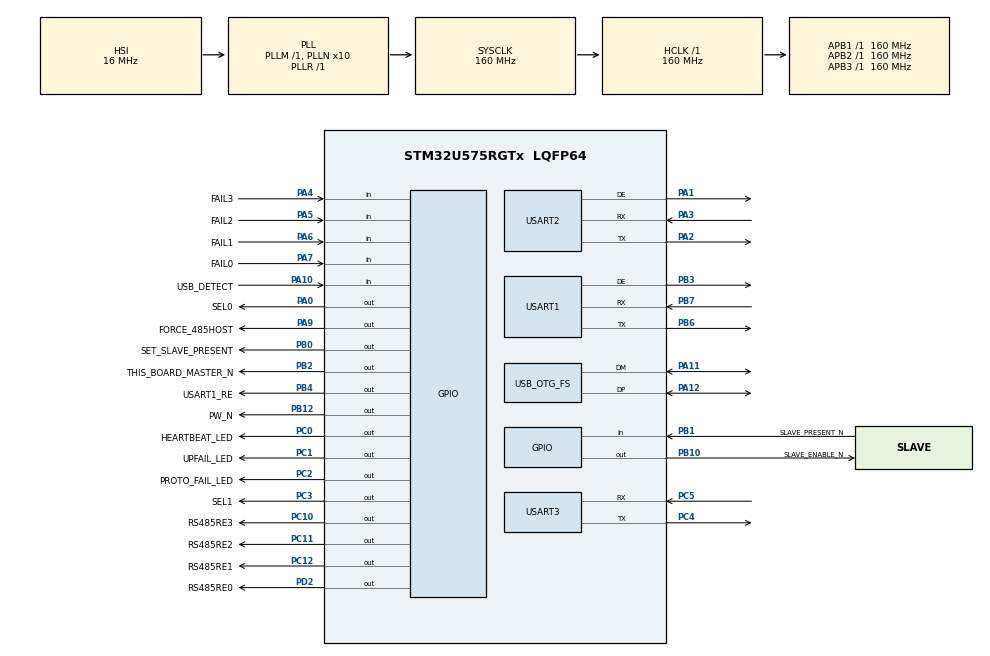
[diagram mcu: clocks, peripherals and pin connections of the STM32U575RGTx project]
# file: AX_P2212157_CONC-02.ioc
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CORTEX_M33_NS.userName=CORTEX_M33
GPDMA1.DIRECTION_GPDMACH0=DMA_MEMORY_TO_PERIPH
GPDMA1.IPHANDLE_GPDMACH0-SIMPLEREQUEST_GPDMACH0=__NULL
GPDMA1.REQUEST_GPDMACH0=GPDMA1_REQUEST_USART2_TX
GPDMA1.SRCINC_GPDMACH0=DMA_SINC_INCREMENTED
GPDMA1.TRANSFERALLOCATEDPORTDEST_GPDMACH0=DMA_DEST_ALLOCATED_PORT1
Mcu.Family=STM32U5
Mcu.Name=STM32U575RGTx
Mcu.Package=LQFP64
NVIC.GPDMA1_Channel0_IRQn=true\:0\:0\:false\:false\:true\:false\:true\:true
NVIC.OTG_FS_IRQn=true\:0\:0\:false\:false\:true\:true\:true\:true
NVIC.PriorityGroup=NVIC_PRIORITYGROUP_4
NVIC.USART1_IRQn=true\:0\:0\:false\:false\:true\:true\:true\:true
NVIC.USART2_IRQn=true\:0\:0\:false\:false\:true\:true\:true\:true
NVIC.USART3_IRQn=true\:0\:0\:false\:false\:true\:true\:true\:true
PA0.GPIO_Label=SEL0
PA0.Signal=GPIO_Output
PA1.Mode=Hardware Flow Control (RS485)
PA1.Signal=USART2_DE
PA10.GPIO_Label=USB_DETECT
PA10.Signal=GPIO_Input
PA11.Mode=Device_Only
PA11.Signal=USB_OTG_FS_DM
PA12.Mode=Device_Only
PA12.Signal=USB_OTG_FS_DP
PA13\ (JTMS/SWDIO).Mode=Serial_Wire
PA13\ (JTMS/SWDIO).Signal=DEBUG_JTMS-SWDIO
PA14\ (JTCK/SWCLK).Mode=Serial_Wire
PA14\ (JTCK/SWCLK).Signal=DEBUG_JTCK-SWCLK
PA2.Mode=Asynchronous
PA2.Signal=USART2_TX
PA3.Mode=Asynchronous
PA3.Signal=USART2_RX
PA4.GPIO_Label=FAIL3
PA4.GPIO_PuPd=GPIO_PULLUP
PA4.Signal=GPIO_Input
PA5.GPIO_Label=FAIL2
PA5.GPIO_PuPd=GPIO_PULLUP
PA5.Signal=GPIO_Input
PA6.GPIO_Label=FAIL1
PA6.GPIO_PuPd=GPIO_PULLUP
PA6.Signal=GPIO_Input
PA7.GPIO_Label=FAIL0
PA7.GPIO_PuPd=GPIO_PULLUP
PA7.Signal=GPIO_Input
PA9.GPIO_Label=FORCE_485HOST
PA9.Signal=GPIO_Output
PB0.GPIO_Label=SET_SLAVE_PRESENT
PB0.Signal=GPIO_Output
PB1.GPIO_Label=SLAVE_PRESENT_N
PB1.Signal=GPIO_Input
PB10.GPIO_Label=SLAVE_ENABLE_N
PB10.Signal=GPIO_Output
PB12.GPIO_Label=PW_N
PB12.Signal=GPIO_Output
PB2.GPIO_Label=THIS_BOARD_MASTER_N
PB2.Signal=GPIO_Output
PB3\ (JTDO/TRACESWO).Mode=Hardware Flow Control (RS485)
PB3\ (JTDO/TRACESWO).Signal=USART1_DE
PB4\ (NJTRST).GPIO_Label=USART1_RE
PB4\ (NJTRST).Signal=GPIO_Output
PB6.Mode=Asynchronous
PB6.Signal=USART1_TX
PB7.Mode=Asynchronous
PB7.Signal=USART1_RX
PC0.GPIO_Label=HEARTBEAT_LED
PC0.Signal=GPIO_Output
PC1.GPIO_Label=UPFAIL_LED
PC1.Signal=GPIO_Output
PC10.GPIO_Label=RS485RE3
PC10.Signal=GPIO_Output
PC11.GPIO_Label=RS485RE2
PC11.Signal=GPIO_Output
PC12.GPIO_Label=RS485RE1
PC12.Signal=GPIO_Output
PC2.GPIO_Label=PROTO_FAIL_LED
PC2.Signal=GPIO_Output
PC3.GPIO_Label=SEL1
PC3.Signal=GPIO_Output
PC4.Mode=Asynchronous
PC4.Signal=USART3_TX
PC5.Mode=Asynchronous
PC5.Signal=USART3_RX
PD2.GPIO_Label=RS485RE0
PD2.Signal=GPIO_Output
ProjectManager.HeapSize=0x200
ProjectManager.StackSize=0x400
ProjectManager.TargetToolchain=STM32CubeIDE
RCC.ADCFreq_Value=16000000
RCC.AHBFreq_Value=160000000
RCC.APB1Freq_Value=160000000
RCC.APB1TimFreq_Value=160000000
RCC.APB2Freq_Value=160000000
RCC.APB2TimFreq_Value=160000000
RCC.APB3Freq_Value=160000000
RCC.CortexFreq_Value=160000000
RCC.EPOD_VALUE=16000000
RCC.HCLKFreq_Value=160000000
RCC.HSE_VALUE=16000000
RCC.HSI48_VALUE=48000000
RCC.HSI_VALUE=16000000
RCC.LSE_VALUE=32768
RCC.LSIDIV_VALUE=32000
RCC.MSI_VALUE=4000000
RCC.PLL1R=1
RCC.PLLFRACN=0
RCC.PLLN=10
RCC.PLLSourceVirtual=RCC_PLLSOURCE_HSI
RCC.SYSCLKFreq_VALUE=160000000
RCC.SYSCLKSource=RCC_SYSCLKSOURCE_PLLCLK
RCC.USBFreq_Value=48000000
RCC.VCOOutputFreq_Value=160000000
USART1.VirtualMode-Asynchronous=VM_ASYNC
USART1.VirtualMode-Hardware\ Flow\ Control\ (RS485)=VM_ASYNC
USART2.VirtualMode-Asynchronous=VM_ASYNC
USART2.VirtualMode-Hardware\ Flow\ Control\ (RS485)=VM_ASYNC
USART3.VirtualMode-Asynchronous=VM_ASYNC
USB_OTG_FS.VirtualMode=Device_Only
VP_CRC_VS_CRC.Mode=CRC_Activate
VP_GPDMA1_VS_GPDMACH0.Mode=SIMPLEREQUEST_GPDMACH0
VP_ICACHE_VS_ENABLE_ICACHE_MEMORY.Mode=Memoryregions
VP_ICACHE_VS_ICACHE.Mode=DefaultMode
VP_LPBAMQUEUE_VS_QUEUE.Mode=QUEUEMODE
VP_LPBAM_VS_SIG1.Mode=SmartRun
VP_LPBAM_VS_SIG4.Mode=LPDMA1
VP_MEMORYMAP_VS_MEMORYMAP.Mode=CurAppReg
VP_PWR_VS_SECSignals.Mode=Security/Privilege
VP_RNG_VS_RNG.Mode=RNG_Activate
board=custom

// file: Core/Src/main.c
/* USER CODE BEGIN Header */
/**
  ******************************************************************************
  * @file           : main.c
  * @brief          : Main program body
  ******************************************************************************
  * @attention
  *
  * Copyright (c) 2024 STMicroelectronics.
  * All rights reserved.
  *
  * This software is licensed under terms that can be found in the LICENSE file
  * in the root directory of this software component.
  * If no LICENSE file comes with this software, it is provided AS-IS.
  *
  ******************************************************************************
  */
/* USER CODE END Header */
#include "main.h"

CRC_HandleTypeDef hcrc;

RNG_HandleTypeDef hrng;

UART_HandleTypeDef huart1;
UART_HandleTypeDef huart2;
UART_HandleTypeDef huart3;
DMA_HandleTypeDef handle_GPDMA1_Channel0;

PCD_HandleTypeDef hpcd_USB_OTG_FS;

void SystemClock_Config(void);
static void MX_GPIO_Init(void);
static void MX_GPDMA1_Init(void);
static void MX_USART1_UART_Init(void);
static void MX_USART2_UART_Init(void);
static void MX_USART3_UART_Init(void);
static void MX_USB_OTG_FS_PCD_Init(void);
static void MX_ICACHE_Init(void);
static void MX_RNG_Init(void);
static void MX_CRC_Init(void);

int main(void)
{

  /* MCU Configuration--------------------------------------------------------*/

  /* Reset of all peripherals, Initializes the Flash interface and the Systick. */
  HAL_Init();

  /* Configure the system clock */
  SystemClock_Config();

  /* USER CODE BEGIN SysInit */
  A_init_mem();

  /* USER CODE END SysInit */

  /* Initialize all configured peripherals */
  MX_GPIO_Init();
  MX_GPDMA1_Init();
  MX_USART1_UART_Init();
  MX_USART2_UART_Init();
  MX_USART3_UART_Init();
  MX_USB_OTG_FS_PCD_Init();
  MX_ICACHE_Init();
  MX_RNG_Init();
  MX_CRC_Init();
  /* USER CODE BEGIN 2 */

	  A_start();

  /* USER CODE END 2 */

  /* Infinite loop */
  /* USER CODE BEGIN WHILE */
  while (1)
  {
	  HAL_GPIO_TogglePin(HEARTBEAT_LED_GPIO_Port, HEARTBEAT_LED_Pin);
	  HAL_Delay(500);

    /* USER CODE END WHILE */

  }
}

void SystemClock_Config(void)
{
  RCC_OscInitTypeDef RCC_OscInitStruct = {0};
  RCC_ClkInitTypeDef RCC_ClkInitStruct = {0};

  /** Configure the main internal regulator output voltage
  */
  if (HAL_PWREx_ControlVoltageScaling(PWR_REGULATOR_VOLTAGE_SCALE1) != HAL_OK)
  {
    Error_Handler();
  }

  /** Initializes the CPU, AHB and APB buses clocks
  */
  RCC_OscInitStruct.OscillatorType = RCC_OSCILLATORTYPE_HSI48|RCC_OSCILLATORTYPE_HSI;
  RCC_OscInitStruct.HSIState = RCC_HSI_ON;
  RCC_OscInitStruct.HSI48State = RCC_HSI48_ON;
  RCC_OscInitStruct.HSICalibrationValue = RCC_HSICALIBRATION_DEFAULT;
  RCC_OscInitStruct.PLL.PLLState = RCC_PLL_ON;
  RCC_OscInitStruct.PLL.PLLSource = RCC_PLLSOURCE_HSI;
  RCC_OscInitStruct.PLL.PLLMBOOST = RCC_PLLMBOOST_DIV1;
  RCC_OscInitStruct.PLL.PLLM = 1;
  RCC_OscInitStruct.PLL.PLLN = 10;
  RCC_OscInitStruct.PLL.PLLP = 2;
  RCC_OscInitStruct.PLL.PLLQ = 2;
  RCC_OscInitStruct.PLL.PLLR = 1;
  RCC_OscInitStruct.PLL.PLLRGE = RCC_PLLVCIRANGE_1;
  RCC_OscInitStruct.PLL.PLLFRACN = 0;
  if (HAL_RCC_OscConfig(&RCC_OscInitStruct) != HAL_OK)
  {
    Error_Handler();
  }

  /** Initializes the CPU, AHB and APB buses clocks
  */
  RCC_ClkInitStruct.ClockType = RCC_CLOCKTYPE_HCLK|RCC_CLOCKTYPE_SYSCLK
                              |RCC_CLOCKTYPE_PCLK1|RCC_CLOCKTYPE_PCLK2
                              |RCC_CLOCKTYPE_PCLK3;
  RCC_ClkInitStruct.SYSCLKSource = RCC_SYSCLKSOURCE_PLLCLK;
  RCC_ClkInitStruct.AHBCLKDivider = RCC_SYSCLK_DIV1;
  RCC_ClkInitStruct.APB1CLKDivider = RCC_HCLK_DIV1;
  RCC_ClkInitStruct.APB2CLKDivider = RCC_HCLK_DIV1;
  RCC_ClkInitStruct.APB3CLKDivider = RCC_HCLK_DIV1;

  if (HAL_RCC_ClockConfig(&RCC_ClkInitStruct, FLASH_LATENCY_4) != HAL_OK)
  {
    Error_Handler();
  }
}

static void MX_CRC_Init(void)
{

  hcrc.Instance = CRC;
  hcrc.Init.DefaultPolynomialUse = DEFAULT_POLYNOMIAL_ENABLE;
  hcrc.Init.DefaultInitValueUse = DEFAULT_INIT_VALUE_ENABLE;
  hcrc.Init.InputDataInversionMode = CRC_INPUTDATA_INVERSION_NONE;
  hcrc.Init.OutputDataInversionMode = CRC_OUTPUTDATA_INVERSION_DISABLE;
  hcrc.InputDataFormat = CRC_INPUTDATA_FORMAT_BYTES;
  if (HAL_CRC_Init(&hcrc) != HAL_OK)
  {
    Error_Handler();
  }

}

static void MX_GPDMA1_Init(void)
{

  /* Peripheral clock enable */
  __HAL_RCC_GPDMA1_CLK_ENABLE();

  /* GPDMA1 interrupt Init */
    HAL_NVIC_SetPriority(GPDMA1_Channel0_IRQn, 0, 0);
    HAL_NVIC_EnableIRQ(GPDMA1_Channel0_IRQn);

}

static void MX_ICACHE_Init(void)
{

  ICACHE_RegionConfigTypeDef pRegionConfig = {0};

  /** Configure and enable a region for memory remapping.
  */
  if (HAL_ICACHE_Disable() != HAL_OK)
  {
    Error_Handler();
  }
  pRegionConfig.BaseAddress = 0x10000000;
  pRegionConfig.RemapAddress = 0x60000000;
  pRegionConfig.Size = ICACHE_REGIONSIZE_2MB;
  pRegionConfig.TrafficRoute = ICACHE_MASTER1_PORT;
  pRegionConfig.OutputBurstType = ICACHE_OUTPUT_BURST_WRAP;
  if (HAL_ICACHE_EnableRemapRegion(_NULL, &pRegionConfig) != HAL_OK)
  {
    Error_Handler();
  }

  /** Enable instruction cache (default 2-ways set associative cache)
  */
  if (HAL_ICACHE_Enable() != HAL_OK)
  {
    Error_Handler();
  }

}

static void MX_RNG_Init(void)
{

  hrng.Instance = RNG;
  hrng.Init.ClockErrorDetection = RNG_CED_ENABLE;
  if (HAL_RNG_Init(&hrng) != HAL_OK)
  {
    Error_Handler();
  }

}

static void MX_USART1_UART_Init(void)
{

  huart1.Instance = USART1;
  huart1.Init.BaudRate = 115200;
  huart1.Init.WordLength = UART_WORDLENGTH_8B;
  huart1.Init.StopBits = UART_STOPBITS_1;
  huart1.Init.Parity = UART_PARITY_NONE;
  huart1.Init.Mode = UART_MODE_TX_RX;
  huart1.Init.HwFlowCtl = UART_HWCONTROL_NONE;
  huart1.Init.OverSampling = UART_OVERSAMPLING_16;
  huart1.Init.OneBitSampling = UART_ONE_BIT_SAMPLE_DISABLE;
  huart1.Init.ClockPrescaler = UART_PRESCALER_DIV1;
  huart1.AdvancedInit.AdvFeatureInit = UART_ADVFEATURE_NO_INIT;
  if (HAL_RS485Ex_Init(&huart1, UART_DE_POLARITY_HIGH, 0, 0) != HAL_OK)
  {
    Error_Handler();
  }
  if (HAL_UARTEx_SetTxFifoThreshold(&huart1, UART_TXFIFO_THRESHOLD_1_8) != HAL_OK)
  {
    Error_Handler();
  }
  if (HAL_UARTEx_SetRxFifoThreshold(&huart1, UART_RXFIFO_THRESHOLD_1_8) != HAL_OK)
  {
    Error_Handler();
  }
  if (HAL_UARTEx_DisableFifoMode(&huart1) != HAL_OK)
  {
    Error_Handler();
  }

}

static void MX_USART2_UART_Init(void)
{

  huart2.Instance = USART2;
  huart2.Init.BaudRate = 115200;
  huart2.Init.WordLength = UART_WORDLENGTH_8B;
  huart2.Init.StopBits = UART_STOPBITS_1;
  huart2.Init.Parity = UART_PARITY_NONE;
  huart2.Init.Mode = UART_MODE_TX_RX;
  huart2.Init.HwFlowCtl = UART_HWCONTROL_NONE;
  huart2.Init.OverSampling = UART_OVERSAMPLING_16;
  huart2.Init.OneBitSampling = UART_ONE_BIT_SAMPLE_DISABLE;
  huart2.Init.ClockPrescaler = UART_PRESCALER_DIV1;
  huart2.AdvancedInit.AdvFeatureInit = UART_ADVFEATURE_NO_INIT;
  if (HAL_RS485Ex_Init(&huart2, UART_DE_POLARITY_HIGH, 0, 0) != HAL_OK)
  {
    Error_Handler();
  }
  if (HAL_UARTEx_SetTxFifoThreshold(&huart2, UART_TXFIFO_THRESHOLD_1_8) != HAL_OK)
  {
    Error_Handler();
  }
  if (HAL_UARTEx_SetRxFifoThreshold(&huart2, UART_RXFIFO_THRESHOLD_1_8) != HAL_OK)
  {
    Error_Handler();
  }
  if (HAL_UARTEx_DisableFifoMode(&huart2) != HAL_OK)
  {
    Error_Handler();
  }

}

static void MX_USART3_UART_Init(void)
{

  huart3.Instance = USART3;
  huart3.Init.BaudRate = 115200;
  huart3.Init.WordLength = UART_WORDLENGTH_8B;
  huart3.Init.StopBits = UART_STOPBITS_1;
  huart3.Init.Parity = UART_PARITY_NONE;
  huart3.Init.Mode = UART_MODE_TX_RX;
  huart3.Init.HwFlowCtl = UART_HWCONTROL_NONE;
  huart3.Init.OverSampling = UART_OVERSAMPLING_16;
  huart3.Init.OneBitSampling = UART_ONE_BIT_SAMPLE_DISABLE;
  huart3.Init.ClockPrescaler = UART_PRESCALER_DIV1;
  huart3.AdvancedInit.AdvFeatureInit = UART_ADVFEATURE_NO_INIT;
  if (HAL_UART_Init(&huart3) != HAL_OK)
  {
    Error_Handler();
  }
  if (HAL_UARTEx_SetTxFifoThreshold(&huart3, UART_TXFIFO_THRESHOLD_1_8) != HAL_OK)
  {
    Error_Handler();
  }
  if (HAL_UARTEx_SetRxFifoThreshold(&huart3, UART_RXFIFO_THRESHOLD_1_8) != HAL_OK)
  {
    Error_Handler();
  }
  if (HAL_UARTEx_DisableFifoMode(&huart3) != HAL_OK)
  {
    Error_Handler();
  }

}

static void MX_USB_OTG_FS_PCD_Init(void)
{

  hpcd_USB_OTG_FS.Instance = USB_OTG_FS;
  hpcd_USB_OTG_FS.Init.dev_endpoints = 6;
  hpcd_USB_OTG_FS.Init.speed = PCD_SPEED_FULL;
  hpcd_USB_OTG_FS.Init.phy_itface = PCD_PHY_EMBEDDED;
  hpcd_USB_OTG_FS.Init.Sof_enable = DISABLE;
  hpcd_USB_OTG_FS.Init.low_power_enable = DISABLE;
  hpcd_USB_OTG_FS.Init.lpm_enable = DISABLE;
  hpcd_USB_OTG_FS.Init.battery_charging_enable = DISABLE;
  hpcd_USB_OTG_FS.Init.use_dedicated_ep1 = DISABLE;
  hpcd_USB_OTG_FS.Init.vbus_sensing_enable = DISABLE;
  hpcd_USB_OTG_FS.Init.dma_enable = DISABLE;
  if (HAL_PCD_Init(&hpcd_USB_OTG_FS) != HAL_OK)
  {
    Error_Handler();
  }

}

static void MX_GPIO_Init(void)
{
  GPIO_InitTypeDef GPIO_InitStruct = {0};

  /* GPIO Ports Clock Enable */
  __HAL_RCC_GPIOC_CLK_ENABLE();
  __HAL_RCC_GPIOA_CLK_ENABLE();
  __HAL_RCC_GPIOB_CLK_ENABLE();
  __HAL_RCC_GPIOD_CLK_ENABLE();

  /*Configure GPIO pin Output Level */
  HAL_GPIO_WritePin(GPIOC, HEARTBEAT_LED_Pin|UPFAIL_LED_Pin|PROTO_FAIL_LED_Pin|SEL1_Pin
                          |RS485RE3_Pin|RS485RE2_Pin|RS485RE1_Pin, GPIO_PIN_RESET);

  /*Configure GPIO pin Output Level */
  HAL_GPIO_WritePin(GPIOA, SEL0_Pin|FORCE_485HOST_Pin, GPIO_PIN_RESET);

  /*Configure GPIO pin Output Level */
  HAL_GPIO_WritePin(GPIOB, SET_SLAVE_PRESENT_Pin|THIS_BOARD_MASTER_N_Pin|SLAVE_ENABLE_N_Pin|PW_N_Pin
                          |USART1_RE_Pin, GPIO_PIN_RESET);

  /*Configure GPIO pin Output Level */
  HAL_GPIO_WritePin(RS485RE0_GPIO_Port, RS485RE0_Pin, GPIO_PIN_RESET);

  /*Configure GPIO pins : HEARTBEAT_LED_Pin UPFAIL_LED_Pin PROTO_FAIL_LED_Pin SEL1_Pin
                           RS485RE3_Pin RS485RE2_Pin RS485RE1_Pin */
  GPIO_InitStruct.Pin = HEARTBEAT_LED_Pin|UPFAIL_LED_Pin|PROTO_FAIL_LED_Pin|SEL1_Pin
                          |RS485RE3_Pin|RS485RE2_Pin|RS485RE1_Pin;
  GPIO_InitStruct.Mode = GPIO_MODE_OUTPUT_PP;
  GPIO_InitStruct.Pull = GPIO_NOPULL;
  GPIO_InitStruct.Speed = GPIO_SPEED_FREQ_LOW;
  HAL_GPIO_Init(GPIOC, &GPIO_InitStruct);

  /*Configure GPIO pins : SEL0_Pin FORCE_485HOST_Pin */
  GPIO_InitStruct.Pin = SEL0_Pin|FORCE_485HOST_Pin;
  GPIO_InitStruct.Mode = GPIO_MODE_OUTPUT_PP;
  GPIO_InitStruct.Pull = GPIO_NOPULL;
  GPIO_InitStruct.Speed = GPIO_SPEED_FREQ_LOW;
  HAL_GPIO_Init(GPIOA, &GPIO_InitStruct);

  /*Configure GPIO pins : FAIL3_Pin FAIL2_Pin FAIL1_Pin FAIL0_Pin */
  GPIO_InitStruct.Pin = FAIL3_Pin|FAIL2_Pin|FAIL1_Pin|FAIL0_Pin;
  GPIO_InitStruct.Mode = GPIO_MODE_INPUT;
  GPIO_InitStruct.Pull = GPIO_PULLUP;
  HAL_GPIO_Init(GPIOA, &GPIO_InitStruct);

  /*Configure GPIO pins : SET_SLAVE_PRESENT_Pin THIS_BOARD_MASTER_N_Pin SLAVE_ENABLE_N_Pin PW_N_Pin
                           USART1_RE_Pin */
  GPIO_InitStruct.Pin = SET_SLAVE_PRESENT_Pin|THIS_BOARD_MASTER_N_Pin|SLAVE_ENABLE_N_Pin|PW_N_Pin
                          |USART1_RE_Pin;
  GPIO_InitStruct.Mode = GPIO_MODE_OUTPUT_PP;
  GPIO_InitStruct.Pull = GPIO_NOPULL;
  GPIO_InitStruct.Speed = GPIO_SPEED_FREQ_LOW;
  HAL_GPIO_Init(GPIOB, &GPIO_InitStruct);

  /*Configure GPIO pin : SLAVE_PRESENT_N_Pin */
  GPIO_InitStruct.Pin = SLAVE_PRESENT_N_Pin;
  GPIO_InitStruct.Mode = GPIO_MODE_INPUT;
  GPIO_InitStruct.Pull = GPIO_NOPULL;
  HAL_GPIO_Init(SLAVE_PRESENT_N_GPIO_Port, &GPIO_InitStruct);

  /*Configure GPIO pin : USB_DETECT_Pin */
  GPIO_InitStruct.Pin = USB_DETECT_Pin;
  GPIO_InitStruct.Mode = GPIO_MODE_INPUT;
  GPIO_InitStruct.Pull = GPIO_NOPULL;
  HAL_GPIO_Init(USB_DETECT_GPIO_Port, &GPIO_InitStruct);

  /*Configure GPIO pin : RS485RE0_Pin */
  GPIO_InitStruct.Pin = RS485RE0_Pin;
  GPIO_InitStruct.Mode = GPIO_MODE_OUTPUT_PP;
  GPIO_InitStruct.Pull = GPIO_NOPULL;
  GPIO_InitStruct.Speed = GPIO_SPEED_FREQ_LOW;
  HAL_GPIO_Init(RS485RE0_GPIO_Port, &GPIO_InitStruct);

}

void Error_Handler(void)
{
  __disable_irq();
  while (1)
  {
  }
}
